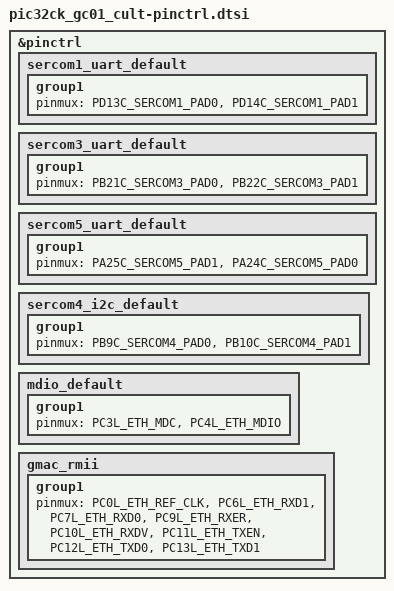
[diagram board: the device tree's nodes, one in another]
/*
 * Copyright (c) 2026 Microchip Technology Inc.
 *
 * SPDX-License-Identifier: Apache-2.0
 */

#include <dt-bindings/pic32c/pic32ck_sg_gc/pic32ck_gc01/pic32ck2051gc01144-pinctrl.h>

&pinctrl {
	sercom1_uart_default: sercom1_uart_default {
		group1 {
			pinmux = <PD13C_SERCOM1_PAD0>,
				 <PD14C_SERCOM1_PAD1>;
		};
	};

	sercom3_uart_default: sercom3_uart_default {
		group1 {
			pinmux = <PB21C_SERCOM3_PAD0>,
				 <PB22C_SERCOM3_PAD1>;
		};
	};

	sercom5_uart_default: sercom5_uart_default {
		group1 {
			pinmux = <PA25C_SERCOM5_PAD1>,
				 <PA24C_SERCOM5_PAD0>;
		};
	};

	sercom4_i2c_default: sercom4_i2c_default {
		group1 {
			pinmux = <PB9C_SERCOM4_PAD0>,
				 <PB10C_SERCOM4_PAD1>;
		};
	};

	mdio_default: mdio_default {
		group1 {
			pinmux = <PC3L_ETH_MDC>,
				 <PC4L_ETH_MDIO>;
		};
	};

	gmac_rmii: gmac_rmii {
		group1 {
			pinmux = <PC0L_ETH_REF_CLK>,
				 <PC6L_ETH_RXD1>,
				 <PC7L_ETH_RXD0>,
				 <PC9L_ETH_RXER>,
				 <PC10L_ETH_RXDV>,
				 <PC11L_ETH_TXEN>,
				 <PC12L_ETH_TXD0>,
				 <PC13L_ETH_TXD1>;
		};
	};
};
